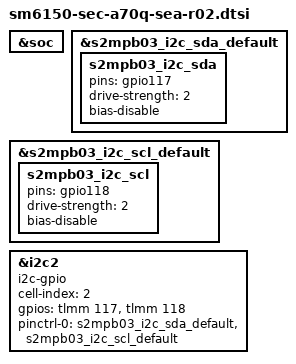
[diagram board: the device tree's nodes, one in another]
/* Copyright (c) 2018, The Linux Foundation. All rights reserved.
 *
 * This program is free software; you can redistribute it and/or modify
 * it under the terms of the GNU General Public License version 2 and
 * only version 2 as published by the Free Software Foundation.
 *
 * This program is distributed in the hope that it will be useful,
 * but WITHOUT ANY WARRANTY; without even the implied warranty of
 * MERCHANTABILITY or FITNESS FOR A PARTICULAR PURPOSE.  See the
 * GNU General Public License for more details.
 */

#include "sm6150-sec-a70q-sea-r01.dtsi"

&soc {
	
};

&s2mpb03_i2c_sda_default {
	s2mpb03_i2c_sda {
		pins = "gpio117";
		drive-strength = <2>;
		/delete-property/bias-pull-up;
		bias-disable;
	};
};

&s2mpb03_i2c_scl_default {
	s2mpb03_i2c_scl {
		pins = "gpio118";
		drive-strength = <2>;
		/delete-property/bias-pull-up;
		bias-disable;
	};
};

/* S2MPB03 Camera PMIC */
&i2c2 {
	cell-index = <2>;
	compatible = "i2c-gpio";
	gpios = <&tlmm 117 0 /* sda */
			 &tlmm 118 0 /* scl */
	>;
	pinctrl-names = "default";
	pinctrl-0 = <&s2mpb03_i2c_sda_default &s2mpb03_i2c_scl_default>;
};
